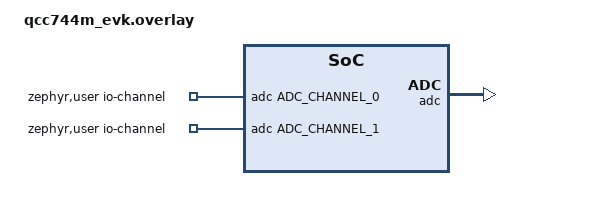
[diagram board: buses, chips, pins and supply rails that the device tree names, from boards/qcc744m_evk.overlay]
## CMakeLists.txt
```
cmake_minimum_required(VERSION 3.20.0)

find_package(Zephyr REQUIRED HINTS $ENV{ZEPHYR_BASE})
project(moth_app)

target_include_directories(app PRIVATE include)
target_sources(app PRIVATE
  src/main.c
  src/adc_reader.c
  src/light_acquisition.c
  src/phototaxis.c
)
```

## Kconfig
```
source "Kconfig.zephyr"

menu "Moth application"

config MOTH_PHOTOTAXIS_MINIMUM_LIGHT
	int "Minimum light level"
	default 100
	range 0 4095
	help
		Minimum background-subtracted light level required before the
		phototaxis controller will move. If both sensors are below this
		value, the controller requests stop.

config MOTH_PHOTOTAXIS_DEADBAND
	int "Phototaxis deadband"
	default 80
	range 0 4095
	help
		Maximum absolute left/right light difference treated as equal.
		Within this range the controller requests forward motion.

config MOTH_PHOTOTAXIS_BASE_SPEED
	int "Phototaxis base speed"
	default 300
	range 0 32767
	help
		Nominal speed requested for each wheel during forward motion.

config MOTH_PHOTOTAXIS_TURN_GAIN
	int "Phototaxis turn gain"
	default 500
	range 0 32767
	help
		Maximum speed correction applied at the full background-subtracted
		ADC difference. Higher values produce sharper turns.

config MOTH_PHOTOTAXIS_MAXIMUM_SPEED
	int "Phototaxis maximum speed"
	default 600
	range 0 32767
	help
		Upper bound applied independently to each wheel speed request.

config MOTH_LIGHT_CALIBRATION_SAMPLES
	int "Light calibration sample count"
	default 32
	range 8 64
	help
		Number of raw ADC samples collected per sensor during startup
		calibration. The median is used as the ambient background level.

config MOTH_LIGHT_CALIBRATION_SETTLE_MS
	int "Light calibration settle time"
	default 500
	range 0 5000
	help
		Time to keep the robot stationary before collecting calibration
		samples, allowing the ADC and sensors to settle.

config MOTH_LIGHT_MIN_NOISE_MARGIN
	int "Minimum light noise margin"
	default 16
	range 0 2048
	help
		Minimum number of ADC counts removed after background subtraction.
		This prevents small ambient fluctuations from causing movement.

config MOTH_LIGHT_NOISE_MULTIPLIER
	int "Light noise multiplier"
	default 3
	range 1 8
	help
		Multiplier applied to the measured median absolute deviation during
		calibration to create a per-sensor noise margin.

config MOTH_LIGHT_BACKGROUND_TRACK_LIMIT
	int "Background tracking limit"
	default 64
	range 0 4095
	help
		Background tracking is allowed only while both sensors remain below
		this background-subtracted level. This avoids slowly absorbing a
		strong target light into the ambient baseline.

config MOTH_LIGHT_BACKGROUND_TRACK_SHIFT
	int "Background tracking speed"
	default 8
	range 1 15
	help
		Power-of-two tracking divisor. A value of 8 means the baseline moves
		by one 256th of the difference per update.

endmenu
```

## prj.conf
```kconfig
CONFIG_ADC=y

CONFIG_LOG=y
CONFIG_LOG_MODE_IMMEDIATE=y
CONFIG_LOG_DEFAULT_LEVEL=3
CONFIG_SERIAL=y
CONFIG_CONSOLE=y
CONFIG_UART_CONSOLE=y

CONFIG_ASSERT=y
CONFIG_MAIN_STACK_SIZE=2048
CONFIG_SYSTEM_WORKQUEUE_STACK_SIZE=2048
```

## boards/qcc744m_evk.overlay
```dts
#include <zephyr/dt-bindings/adc/adc.h>
#include <zephyr/dt-bindings/adc/qcc74x-adc.h>
#include <zephyr/dt-bindings/pinctrl/qc7xx-qcc74x-pinctrl.h>

/ {
	zephyr,user {
		/* Provisional wiring: left sensor on GPIO20/ADC0, right on GPIO19/ADC1. */
		io-channels = <&adc ADC_CHANNEL_0>, <&adc ADC_CHANNEL_1>;
		zephyr,gain = "ADC_GAIN_1";
		zephyr,reference = "ADC_REF_INTERNAL";
		zephyr,acquisition-time = <ADC_ACQ_TIME_DEFAULT>;
		zephyr,resolution = <12>;
		zephyr,oversampling = <0>;
	};
};

&pinctrl {
	moth_adc_default: moth_adc_default {
		group1 {
			pinmux = <GPIO20_ADC_CH0>, <GPIO19_ADC_CH1>;
		};
	};
};

&adc {
	status = "okay";
	pinctrl-0 = <&moth_adc_default>;
	pinctrl-names = "default";
};
```

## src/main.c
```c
#include <zephyr/logging/log.h>

#include <moth/light_acquisition.h>
#include <moth/phototaxis.h>

LOG_MODULE_REGISTER(moth_app, LOG_LEVEL_INF);

int main(void)
{
	int rc;

	LOG_INF("Moth ADC/light/phototaxis pipeline starting");

	rc = moth_light_acquisition_start();
	if (rc != 0) {
		LOG_ERR("Could not start light acquisition: %d", rc);
		return rc;
	}

	rc = moth_phototaxis_start();
	if (rc != 0) {
		LOG_ERR("Could not start phototaxis controller: %d", rc);
		return rc;
	}

	return 0;
}
```

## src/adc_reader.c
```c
#include <errno.h>

#include <zephyr/devicetree.h>
#include <zephyr/drivers/adc.h>
#include <zephyr/logging/log.h>
#include <zephyr/sys/util.h>

#include <moth/adc_reader.h>

LOG_MODULE_REGISTER(moth_adc_reader, LOG_LEVEL_INF);

#define MOTH_USER_NODE DT_PATH(zephyr_user)
#define MOTH_ADC_CHANNEL_COUNT 2

static const struct adc_dt_spec adc_channels[MOTH_ADC_CHANNEL_COUNT] = {
	ADC_DT_SPEC_GET_BY_IDX(MOTH_USER_NODE, 0),
	ADC_DT_SPEC_GET_BY_IDX(MOTH_USER_NODE, 1),
};

int moth_adc_reader_init(void)
{
	for (size_t i = 0; i < ARRAY_SIZE(adc_channels); ++i) {
		if (!adc_is_ready_dt(&adc_channels[i])) {
			LOG_ERR("ADC channel %u is not ready", i);
			return -ENODEV;
		}

		int rc = adc_channel_setup_dt(&adc_channels[i]);
		if (rc != 0) {
			LOG_ERR("ADC channel %u setup failed: %d", i, rc);
			return rc;
		}

		LOG_INF("ADC channel %u ready (channel id %d)", i,
			adc_channels[i].channel_id);
	}

	return 0;
}

int moth_adc_reader_read(struct moth_adc_sample *sample)
{
	if (sample == NULL) {
		return -EINVAL;
	}

	for (size_t i = 0; i < ARRAY_SIZE(adc_channels); ++i) {
		struct adc_sequence sequence = { 0 };
		int16_t value = 0;

		int rc = adc_sequence_init_dt(&adc_channels[i], &sequence);
		if (rc != 0) {
			return rc;
		}

		sequence.buffer = &value;
		sequence.buffer_size = sizeof(value);

		rc = adc_read_dt(&adc_channels[i], &sequence);
		if (rc != 0) {
			return rc;
		}

		if (i == 0) {
			sample->left = (uint16_t)value;
		} else {
			sample->right = (uint16_t)value;
		}
	}

	return 0;
}
```

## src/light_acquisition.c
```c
#include <errno.h>
#include <stddef.h>
#include <stdint.h>

#include <zephyr/kernel.h>
#include <zephyr/logging/log.h>
#include <zephyr/sys/util.h>

#include <moth/adc_reader.h>
#include <moth/light_acquisition.h>

LOG_MODULE_REGISTER(moth_light_acquisition, LOG_LEVEL_INF);

#define MOTH_LIGHT_PERIOD_MS 50
#define MOTH_LIGHT_QUEUE_LENGTH 4
#define MOTH_LIGHT_FILTER_SHIFT 2
#define MOTH_CALIBRATION_MAX_SAMPLES 64

BUILD_ASSERT(CONFIG_MOTH_LIGHT_CALIBRATION_SAMPLES <=
		     MOTH_CALIBRATION_MAX_SAMPLES,
		     "Calibration sample count exceeds local storage");

K_MSGQ_DEFINE(moth_light_queue,
		      sizeof(struct moth_light_frame),
		      MOTH_LIGHT_QUEUE_LENGTH,
		      sizeof(uint32_t));

K_THREAD_STACK_DEFINE(light_stack, 1024);
static struct k_thread light_thread;

struct moth_light_calibration {
	uint16_t ambient_left;
	uint16_t ambient_right;
	uint16_t margin_left;
	uint16_t margin_right;
	bool ready;
};

static uint16_t calibration_left[MOTH_CALIBRATION_MAX_SAMPLES];
static uint16_t calibration_right[MOTH_CALIBRATION_MAX_SAMPLES];

static uint16_t filter_sample(uint16_t previous, uint16_t current,
			      bool initialized)
{
	if (!initialized) {
		return current;
	}

	int32_t delta = (int32_t)current - (int32_t)previous;
	return (uint16_t)((int32_t)previous +
				  (delta >> MOTH_LIGHT_FILTER_SHIFT));
}

static void sort_samples(uint16_t *samples, size_t count)
{
	for (size_t i = 1; i < count; ++i) {
		uint16_t value = samples[i];
		size_t j = i;

		while ((j > 0) && (samples[j - 1] > value)) {
			samples[j] = samples[j - 1];
			--j;
		}
		samples[j] = value;
	}
}

static uint16_t absolute_difference(uint16_t first, uint16_t second)
{
	return first >= second ? first - second : second - first;
}

static uint16_t calculate_noise_margin(uint16_t *samples, size_t count,
					       uint16_t ambient)
{
	/* Convert the sample array into absolute deviations from the median. */
	for (size_t i = 0; i < count; ++i) {
		samples[i] = absolute_difference(samples[i], ambient);
	}
	sort_samples(samples, count);

	uint32_t margin = (uint32_t)samples[count / 2] *
			  CONFIG_MOTH_LIGHT_NOISE_MULTIPLIER;
	if (margin < CONFIG_MOTH_LIGHT_MIN_NOISE_MARGIN) {
		margin = CONFIG_MOTH_LIGHT_MIN_NOISE_MARGIN;
	}
	if (margin > UINT16_MAX) {
		margin = UINT16_MAX;
	}

	return (uint16_t)margin;
}

static int calibrate_light(struct moth_light_calibration *calibration)
{
	const size_t sample_count = CONFIG_MOTH_LIGHT_CALIBRATION_SAMPLES;
	struct moth_adc_sample sample;

	LOG_INF("Light calibration: keep robot stationary for %d ms",
		CONFIG_MOTH_LIGHT_CALIBRATION_SETTLE_MS);
	k_sleep(K_MSEC(CONFIG_MOTH_LIGHT_CALIBRATION_SETTLE_MS));

	for (size_t i = 0; i < sample_count; ++i) {
		int rc = moth_adc_reader_read(&sample);
		if (rc != 0) {
			LOG_ERR("Light calibration ADC read failed: %d", rc);
			return rc;
		}

		calibration_left[i] = sample.left;
		calibration_right[i] = sample.right;

		if (i + 1 < sample_count) {
			k_sleep(K_MSEC(MOTH_LIGHT_PERIOD_MS));
		}
	}

	sort_samples(calibration_left, sample_count);
	sort_samples(calibration_right, sample_count);

	calibration->ambient_left = calibration_left[sample_count / 2];
	calibration->ambient_right = calibration_right[sample_count / 2];
	calibration->margin_left = calculate_noise_margin(
		calibration_left, sample_count, calibration->ambient_left);
	calibration->margin_right = calculate_noise_margin(
		calibration_right, sample_count, calibration->ambient_right);
	calibration->ready = true;

	LOG_INF("Light calibration ready: ambient L=%u R=%u, margin L=%u R=%u",
		calibration->ambient_left, calibration->ambient_right,
		calibration->margin_left, calibration->margin_right);

	return 0;
}

static uint16_t subtract_background(uint16_t sample, uint16_t ambient)
{
	return sample > ambient ? sample - ambient : 0;
}

static uint16_t subtract_noise_margin(uint16_t signal, uint16_t margin)
{
	return signal > margin ? signal - margin : 0;
}

static uint16_t track_background(uint16_t ambient, uint16_t sample)
{
	int32_t delta = (int32_t)sample - (int32_t)ambient;
	return (uint16_t)((int32_t)ambient +
				  (delta >> CONFIG_MOTH_LIGHT_BACKGROUND_TRACK_SHIFT));
}

static void publish_frame(const struct moth_light_frame *frame)
{
	if (k_msgq_put(&moth_light_queue, frame, K_NO_WAIT) == 0) {
		return;
	}

	/* Keep the controller close to real time if it falls behind. */
	struct moth_light_frame discarded;
	(void)k_msgq_get(&moth_light_queue, &discarded, K_NO_WAIT);
	(void)k_msgq_put(&moth_light_queue, frame, K_NO_WAIT);
}

static void light_thread_entry(void *unused1, void *unused2, void *unused3)
{
	ARG_UNUSED(unused1);
	ARG_UNUSED(unused2);
	ARG_UNUSED(unused3);

	struct moth_adc_sample sample;
	struct moth_light_frame frame = { 0 };
	struct moth_light_calibration calibration = { 0 };
	uint16_t filtered_left = 0;
	uint16_t filtered_right = 0;
	bool filter_initialized = false;
	uint32_t sequence = 0;

	int rc = moth_adc_reader_init();
	if (rc != 0) {
		LOG_ERR("ADC initialization failed: %d", rc);
	}

	while (true) {
		frame = (struct moth_light_frame){
			.sequence = sequence++,
			.ambient_left = calibration.ambient_left,
			.ambient_right = calibration.ambient_right,
			.noise_margin_left = calibration.margin_left,
			.noise_margin_right = calibration.margin_right,
			.valid = false,
			.calibrated = calibration.ready,
		};

		if ((rc == 0) && !calibration.ready) {
			rc = calibrate_light(&calibration);
			frame.calibrated = calibration.ready;
			frame.ambient_left = calibration.ambient_left;
			frame.ambient_right = calibration.ambient_right;
			frame.noise_margin_left = calibration.margin_left;
			frame.noise_margin_right = calibration.margin_right;
		}

		if ((rc == 0) && calibration.ready) {
			rc = moth_adc_reader_read(&sample);
			if (rc == 0) {
				uint16_t left_signal = subtract_background(
					sample.left, calibration.ambient_left);
				uint16_t right_signal = subtract_background(
					sample.right, calibration.ambient_right);

				/* Track only weak background changes. */
				if ((left_signal <= CONFIG_MOTH_LIGHT_BACKGROUND_TRACK_LIMIT) &&
				    (right_signal <= CONFIG_MOTH_LIGHT_BACKGROUND_TRACK_LIMIT)) {
					calibration.ambient_left = track_background(
						calibration.ambient_left, sample.left);
					calibration.ambient_right = track_background(
						calibration.ambient_right, sample.right);
					left_signal = subtract_background(
						sample.left, calibration.ambient_left);
					right_signal = subtract_background(
						sample.right, calibration.ambient_right);
				}

				left_signal = subtract_noise_margin(
					left_signal, calibration.margin_left);
				right_signal = subtract_noise_margin(
					right_signal, calibration.margin_right);

				filtered_left = filter_sample(filtered_left, left_signal,
							      filter_initialized);
				filtered_right = filter_sample(filtered_right, right_signal,
							       filter_initialized);
				frame.left = filtered_left;
				frame.right = filtered_right;
				filter_initialized = true;
				frame.ambient_left = calibration.ambient_left;
				frame.ambient_right = calibration.ambient_right;
				frame.valid = true;
			} else {
				LOG_ERR("ADC read failed: %d", rc);
			}
		}

		publish_frame(&frame);
		k_sleep(K_MSEC(MOTH_LIGHT_PERIOD_MS));

		/* A transient read/init error should not permanently disable acquisition. */
		if (rc != 0) {
			rc = moth_adc_reader_init();
		}
	}
}

int moth_light_acquisition_start(void)
{
	k_thread_create(&light_thread, light_stack, K_THREAD_STACK_SIZEOF(light_stack),
			light_thread_entry, NULL, NULL, NULL, 5, 0, K_NO_WAIT);
	return 0;
}
```

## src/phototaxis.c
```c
#include <stdint.h>

#include <zephyr/kernel.h>
#include <zephyr/logging/log.h>

#include <moth/light_acquisition.h>
#include <moth/phototaxis.h>

LOG_MODULE_REGISTER(moth_phototaxis, LOG_LEVEL_INF);

#define MOTH_ADC_FULL_SCALE 4095

K_THREAD_STACK_DEFINE(phototaxis_stack, 1024);
static struct k_thread phototaxis_thread;

static int16_t clamp_speed(int32_t speed, int16_t maximum)
{
	if (speed < 0) {
		return 0;
	}
	if (speed > maximum) {
		return maximum;
	}
	return (int16_t)speed;
}

void moth_phototaxis_compute(const struct moth_light_frame *frame,
				     const struct moth_phototaxis_config *config,
				     struct moth_drive_request *request)
{
	if ((frame == NULL) || (config == NULL) || (request == NULL)) {
		return;
	}

	request->valid = frame->valid && frame->calibrated;
	request->motion = MOTH_MOTION_STOP;
	request->left_speed = 0;
	request->right_speed = 0;

	if (!frame->valid || !frame->calibrated ||
	    ((frame->left < config->minimum_light) &&
	     (frame->right < config->minimum_light))) {
		return;
	}

	int32_t difference = (int32_t)frame->left - (int32_t)frame->right;
	int32_t magnitude = difference < 0 ? -difference : difference;

	if (magnitude <= config->deadband) {
		request->motion = MOTH_MOTION_FORWARD;
		request->left_speed = clamp_speed(config->base_speed,
							 config->maximum_speed);
		request->right_speed = clamp_speed(config->base_speed,
							  config->maximum_speed);
		return;
	}

	int32_t correction = (magnitude * config->turn_gain) / MOTH_ADC_FULL_SCALE;
	if (correction < 1) {
		correction = 1;
	}

	int32_t left_speed = config->base_speed;
	int32_t right_speed = config->base_speed;

	if (difference > 0) {
		/* Left is brighter: slow the left wheel to turn toward the light. */
		request->motion = MOTH_MOTION_TURN_LEFT;
		left_speed -= correction;
		right_speed += correction;
	} else {
		request->motion = MOTH_MOTION_TURN_RIGHT;
		left_speed += correction;
		right_speed -= correction;
	}

	request->left_speed = clamp_speed(left_speed, config->maximum_speed);
	request->right_speed = clamp_speed(right_speed, config->maximum_speed);
}

static const char *motion_name(enum moth_motion motion)
{
	switch (motion) {
	case MOTH_MOTION_FORWARD:
		return "forward";
	case MOTH_MOTION_TURN_LEFT:
		return "left";
	case MOTH_MOTION_TURN_RIGHT:
		return "right";
	case MOTH_MOTION_STOP:
	default:
		return "stop";
	}
}

static void phototaxis_thread_entry(void *unused1, void *unused2, void *unused3)
{
	ARG_UNUSED(unused1);
	ARG_UNUSED(unused2);
	ARG_UNUSED(unused3);

	const struct moth_phototaxis_config config = {
		.minimum_light = CONFIG_MOTH_PHOTOTAXIS_MINIMUM_LIGHT,
		.deadband = CONFIG_MOTH_PHOTOTAXIS_DEADBAND,
		.base_speed = CONFIG_MOTH_PHOTOTAXIS_BASE_SPEED,
		.turn_gain = CONFIG_MOTH_PHOTOTAXIS_TURN_GAIN,
		.maximum_speed = CONFIG_MOTH_PHOTOTAXIS_MAXIMUM_SPEED,
	};

	struct moth_light_frame frame;
	struct moth_drive_request request;
	enum moth_motion previous_motion = MOTH_MOTION_STOP;

	while (true) {
		if (k_msgq_get(&moth_light_queue, &frame, K_FOREVER) != 0) {
			continue;
		}

		moth_phototaxis_compute(&frame, &config, &request);

		if (request.motion != previous_motion) {
			LOG_INF("Phototaxis: %s (L=%d R=%d, valid=%d)",
				motion_name(request.motion), request.left_speed,
				request.right_speed, request.valid);
			previous_motion = request.motion;
		} else {
			LOG_DBG("Phototaxis: %s (L=%d R=%d)",
				motion_name(request.motion), request.left_speed,
				request.right_speed);
		}
	}
}

int moth_phototaxis_start(void)
{
	k_thread_create(&phototaxis_thread, phototaxis_stack,
			K_THREAD_STACK_SIZEOF(phototaxis_stack),
			phototaxis_thread_entry, NULL, NULL, NULL, 5, 0, K_NO_WAIT);
	return 0;
}
```
